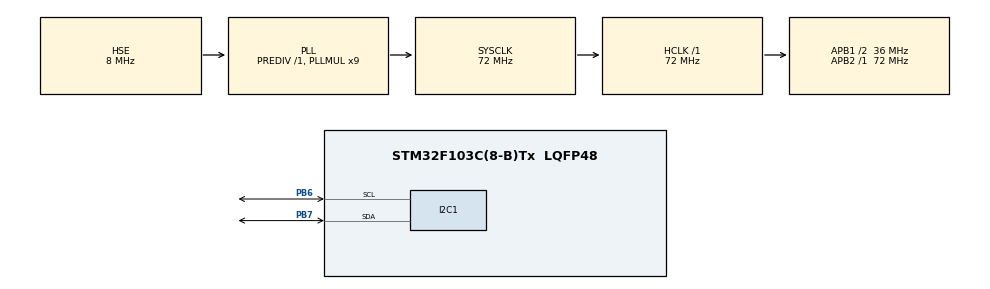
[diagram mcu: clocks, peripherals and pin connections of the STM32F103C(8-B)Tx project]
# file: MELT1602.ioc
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I2C1.I2C_Mode=I2C_Fast
Mcu.Family=STM32F1
Mcu.Name=STM32F103C(8-B)Tx
Mcu.Package=LQFP48
NVIC.PriorityGroup=NVIC_PRIORITYGROUP_4
PA13.Mode=Serial_Wire
PA13.Signal=SYS_JTMS-SWDIO
PA14.Mode=Serial_Wire
PA14.Signal=SYS_JTCK-SWCLK
PB6.Mode=I2C
PB6.Signal=I2C1_SCL
PB7.Mode=I2C
PB7.Signal=I2C1_SDA
PD0-OSC_IN.Mode=HSE-External-Oscillator
PD0-OSC_IN.Signal=RCC_OSC_IN
PD1-OSC_OUT.Mode=HSE-External-Oscillator
PD1-OSC_OUT.Signal=RCC_OSC_OUT
ProjectManager.HeapSize=0x200
ProjectManager.StackSize=0x400
ProjectManager.TargetToolchain=STM32CubeIDE
RCC.AHBFreq_Value=72000000
RCC.APB1CLKDivider=RCC_HCLK_DIV2
RCC.APB1Freq_Value=36000000
RCC.APB1TimFreq_Value=72000000
RCC.APB2Freq_Value=72000000
RCC.APB2TimFreq_Value=72000000
RCC.HCLKFreq_Value=72000000
RCC.PLLMUL=RCC_PLL_MUL9
RCC.PLLSourceVirtual=RCC_PLLSOURCE_HSE
RCC.SYSCLKFreq_VALUE=72000000
RCC.SYSCLKSource=RCC_SYSCLKSOURCE_PLLCLK
RCC.USBFreq_Value=72000000
board=custom

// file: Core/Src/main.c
/* USER CODE BEGIN Header */
/**
 ******************************************************************************
 * @file           : main.c
 * @brief          : Main program body
 ******************************************************************************
 * @attention
 *
 * <h2><center>&copy; Copyright (c) 2020 STMicroelectronics.
 * All rights reserved.</center></h2>
 *
 * This software component is licensed by ST under BSD 3-Clause license,
 * the "License"; You may not use this file except in compliance with the
 * License. You may obtain a copy of the License at:
 *                        opensource.org/licenses/BSD-3-Clause
 *
 ******************************************************************************
 */
/* USER CODE END Header */
#include "main.h"
#include <stdio.h>
#include <stdbool.h>
#include "lcd1602_i2c_lib.h"

extern char lcd1602_tx_buffer[40];

/*----Русский алфавит----*/
/*Чего нет, то заменяется латинскими буквами*/

#define RU_B 0xC1 //Б
#define RU_G 0xC3 //Г
#define RU_D 0xC4 //Д
#define RU_Eo 0xA8 //Ё
#define RU_Zh 0xC6//Ж
#define RU_Z 0xC7 //З
#define RU_I 0xC8 //И
#define RU_J 0xC9 //Й
#define RU_L 0xCB //Л
#define RU_P 0xCF //П
#define RU_U 0xD3 //У
#define RU_F 0xD4 //Ф
#define RU_Ts 0xD6 //Ц
#define RU_Ch 0xD7 //Ч
#define RU_Sh 0xD8 //Ш
#define RU_Shch 0xD9 //Щ
#define RU_TZ 0xDA //Ъ
#define RU_Y 0xAB //Ы
#define RU_MZ 0xDC //Ь
#define RU_EE 0xDD //Э
#define RU_Yu 0xDE //Ю
#define RU_Ya 0xDF //Я

/*Чего нет, то заменяется латинскими буквами*/

#define RU_b 0xE1 //б
#define RU_v 0xE2 //в
#define RU_g 0xE3 //г
#define RU_d 0xE4 //д
#define RU_eo 0xB8 //ё
#define RU_zh 0xE6 //ж
#define RU_z 0xE7 //з
#define RU_i 0xE8 //и
#define RU_j 0xE9 //й
#define RU_k 0xEA //к
#define RU_l 0xEB //л
#define RU_m 0xEC //м
#define RU_n 0xED //н
#define RU_p 0xEF //п
#define RU_t 0xF2 //т
#define RU_f 0xF4 //ф
#define RU_ts 0xF6 //ц
#define RU_ch 0xF7 //ч
#define RU_sh 0xF8 //ш
#define RU_shch 0xF9 //щ
#define RU_tz 0xFA //ъ
#define RU_y 0xFB //ы
#define RU_mz 0xFC //ь
#define RU_ee 0xFD //э
#define RU_yu 0xFE //ю
#define RU_ya 0xFF //я

/*----Русский алфавит----*/

I2C_HandleTypeDef hi2c1;

void SystemClock_Config(void);
static void MX_GPIO_Init(void);
static void MX_I2C1_Init(void);

int main(void) {

	/* MCU Configuration--------------------------------------------------------*/

	/* Reset of all peripherals, Initializes the Flash interface and the Systick. */
	HAL_Init();

	/* Configure the system clock */
	SystemClock_Config();

	/* Initialize all configured peripherals */
	MX_GPIO_Init();
	MX_I2C1_Init();
	/* USER CODE BEGIN 2 */
	HAL_Delay(100);
	lcd1602_Init();
	lcd1602_SetCursor(0, 0);
	sprintf(lcd1602_tx_buffer, "%cp%c%ce%c %c%cp", RU_P, RU_i, RU_v, RU_t, RU_m, RU_i);//Привет мир!
	lcd1602_Print_text(lcd1602_tx_buffer);
	/* USER CODE END 2 */

	/* Infinite loop */
	while (1) {

	}
}

void SystemClock_Config(void) {
	RCC_OscInitTypeDef RCC_OscInitStruct = { 0 };
	RCC_ClkInitTypeDef RCC_ClkInitStruct = { 0 };

	/** Initializes the RCC Oscillators according to the specified parameters
	 * in the RCC_OscInitTypeDef structure.
	 */
	RCC_OscInitStruct.OscillatorType = RCC_OSCILLATORTYPE_HSE;
	RCC_OscInitStruct.HSEState = RCC_HSE_ON;
	RCC_OscInitStruct.HSEPredivValue = RCC_HSE_PREDIV_DIV1;
	RCC_OscInitStruct.HSIState = RCC_HSI_ON;
	RCC_OscInitStruct.PLL.PLLState = RCC_PLL_ON;
	RCC_OscInitStruct.PLL.PLLSource = RCC_PLLSOURCE_HSE;
	RCC_OscInitStruct.PLL.PLLMUL = RCC_PLL_MUL9;
	if (HAL_RCC_OscConfig(&RCC_OscInitStruct) != HAL_OK) {
		Error_Handler();
	}
	/** Initializes the CPU, AHB and APB buses clocks
	 */
	RCC_ClkInitStruct.ClockType = RCC_CLOCKTYPE_HCLK | RCC_CLOCKTYPE_SYSCLK | RCC_CLOCKTYPE_PCLK1 | RCC_CLOCKTYPE_PCLK2;
	RCC_ClkInitStruct.SYSCLKSource = RCC_SYSCLKSOURCE_PLLCLK;
	RCC_ClkInitStruct.AHBCLKDivider = RCC_SYSCLK_DIV1;
	RCC_ClkInitStruct.APB1CLKDivider = RCC_HCLK_DIV2;
	RCC_ClkInitStruct.APB2CLKDivider = RCC_HCLK_DIV1;

	if (HAL_RCC_ClockConfig(&RCC_ClkInitStruct, FLASH_LATENCY_2) != HAL_OK) {
		Error_Handler();
	}
}

static void MX_I2C1_Init(void) {

	hi2c1.Instance = I2C1;
	hi2c1.Init.ClockSpeed = 400000;
	hi2c1.Init.DutyCycle = I2C_DUTYCYCLE_2;
	hi2c1.Init.OwnAddress1 = 0;
	hi2c1.Init.AddressingMode = I2C_ADDRESSINGMODE_7BIT;
	hi2c1.Init.DualAddressMode = I2C_DUALADDRESS_DISABLE;
	hi2c1.Init.OwnAddress2 = 0;
	hi2c1.Init.GeneralCallMode = I2C_GENERALCALL_DISABLE;
	hi2c1.Init.NoStretchMode = I2C_NOSTRETCH_DISABLE;
	if (HAL_I2C_Init(&hi2c1) != HAL_OK) {
		Error_Handler();
	}

}

static void MX_GPIO_Init(void) {

	/* GPIO Ports Clock Enable */
	__HAL_RCC_GPIOD_CLK_ENABLE();
	__HAL_RCC_GPIOA_CLK_ENABLE();
	__HAL_RCC_GPIOB_CLK_ENABLE();

}

void Error_Handler(void) {
	__disable_irq();
	while (1) {
	}
}

/************************ (C) COPYRIGHT STMicroelectronics *****END OF FILE****/
